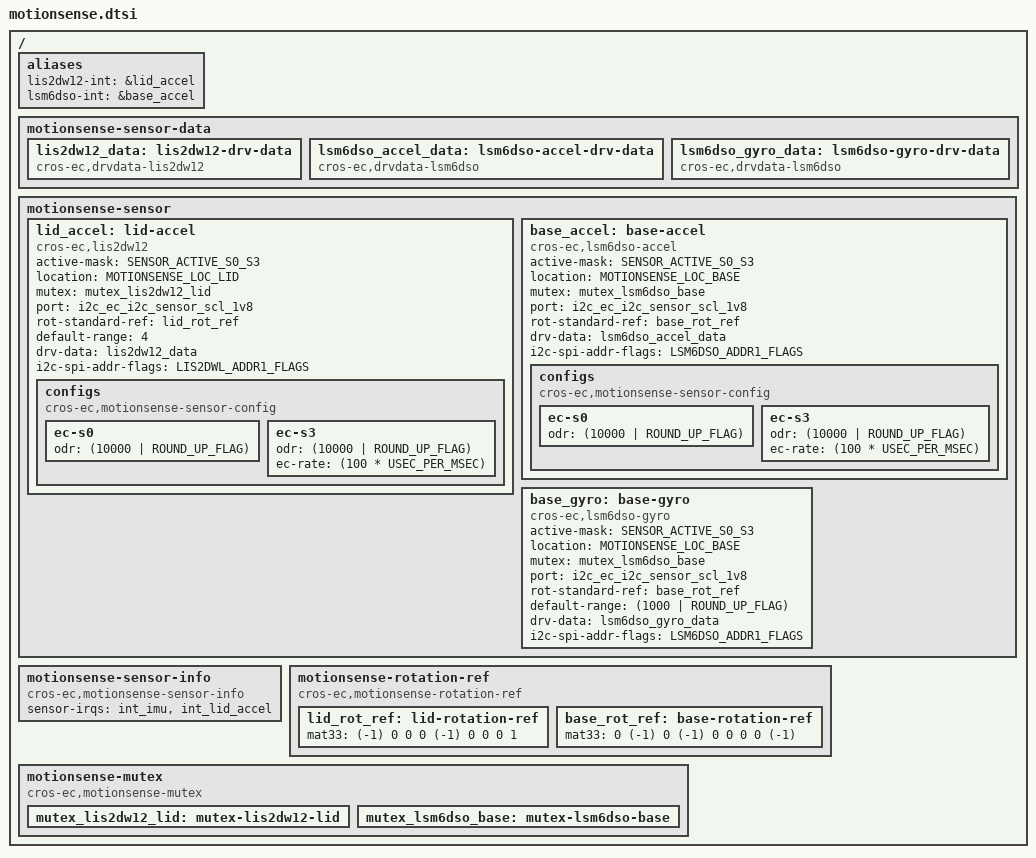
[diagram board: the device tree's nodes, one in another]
/* Copyright 2026 The ChromiumOS Authors
 * Use of this source code is governed by a BSD-style license that can be
 * found in the LICENSE file.
 *
 */

#include <dt-bindings/motionsense/utils.h>

/ {
	aliases {
		/*
		 * motion sense's <>_INT_EVENT is handled
		 * by alias. Using the alias, each driver creates
		 * its own <>_INT_EVENT.
		 */
		lis2dw12-int = &lid_accel;
		lsm6dso-int = &base_accel;
	};

	/*
	 * Driver specific data. A driver-specific data can be shared with
	 * different motion sensors while they are using the same driver.
	 *
	 * If a node's compatible starts with "cros-ec,accelgyro-", it is for
	 * a common structure defined in accelgyro.h.
	 * e.g) compatible = "cros-ec,accelgyro-als-drv-data" is for
	 * "struct als_drv_data_t" in accelgyro.h
	 */
	motionsense-sensor-data {
		lis2dw12_data: lis2dw12-drv-data {
			compatible = "cros-ec,drvdata-lis2dw12";
			status = "okay";
		};

		lsm6dso_accel_data: lsm6dso-accel-drv-data {
			compatible = "cros-ec,drvdata-lsm6dso";
			status = "okay";
		};

		lsm6dso_gyro_data: lsm6dso-gyro-drv-data {
			compatible = "cros-ec,drvdata-lsm6dso";
			status = "okay";
		};
	};

	motionsense-sensor {
		lid_accel: lid-accel {
			compatible = "cros-ec,lis2dw12";
			status = "okay";

			active-mask = "SENSOR_ACTIVE_S0_S3";
			location = "MOTIONSENSE_LOC_LID";
			mutex = <&mutex_lis2dw12_lid>;
			port = <&i2c_ec_i2c_sensor_scl_1v8>;
			rot-standard-ref = <&lid_rot_ref>;
			default-range = <4>; /* to meet CDD 7.3.1/C-1-4 reqs. */
			drv-data = <&lis2dw12_data>;
			i2c-spi-addr-flags = "LIS2DWL_ADDR1_FLAGS";
			configs {
				compatible =
					"cros-ec,motionsense-sensor-config";
				ec-s0 {
					odr = <(10000 | ROUND_UP_FLAG)>;
				};
				ec-s3 {
					odr = <(10000 | ROUND_UP_FLAG)>;
					ec-rate = <(100 * USEC_PER_MSEC)>;
				};
			};
		};

		base_accel: base-accel {
			compatible = "cros-ec,lsm6dso-accel";
			status = "okay";

			active-mask = "SENSOR_ACTIVE_S0_S3";
			location = "MOTIONSENSE_LOC_BASE";
			mutex = <&mutex_lsm6dso_base>;
			port = <&i2c_ec_i2c_sensor_scl_1v8>;
			rot-standard-ref = <&base_rot_ref>;
			drv-data = <&lsm6dso_accel_data>;
			i2c-spi-addr-flags = "LSM6DSO_ADDR1_FLAGS";
			configs {
				compatible =
					"cros-ec,motionsense-sensor-config";
				ec-s0 {
					odr = <(10000 | ROUND_UP_FLAG)>;
				};
				ec-s3 {
					odr = <(10000 | ROUND_UP_FLAG)>;
					ec-rate = <(100 * USEC_PER_MSEC)>;
				};
			};
		};

		base_gyro: base-gyro {
			compatible = "cros-ec,lsm6dso-gyro";
			status = "okay";

			active-mask = "SENSOR_ACTIVE_S0_S3";
			location = "MOTIONSENSE_LOC_BASE";
			mutex = <&mutex_lsm6dso_base>;
			port = <&i2c_ec_i2c_sensor_scl_1v8>;
			rot-standard-ref = <&base_rot_ref>;
			default-range = <(1000 | ROUND_UP_FLAG)>; /* dps */
			drv-data = <&lsm6dso_gyro_data>;
			i2c-spi-addr-flags = "LSM6DSO_ADDR1_FLAGS";
		};
	};

	motionsense-sensor-info {
		compatible = "cros-ec,motionsense-sensor-info";

		/*
		 * list of GPIO interrupts that have to
		 * be enabled at initial stage
		 */
		sensor-irqs = <&int_imu &int_lid_accel>;
	};

	/* Rotation matrix used by drivers. */
	motionsense-rotation-ref {
		compatible = "cros-ec,motionsense-rotation-ref";
		lid_rot_ref: lid-rotation-ref {
			mat33 = <(-1) 0 0
				 0 (-1) 0
				 0 0 1>;
		};
		base_rot_ref: base-rotation-ref {
			mat33 = <0 (-1) 0
				 (-1) 0 0
				 0 0 (-1)>;
		};
	};

	/*
	 * Declare mutexes used by sensor drivers.
	 * A mutex node is used to create an instance of mutex_t.
	 * A mutex node is referenced by a sensor node if the
	 * corresponding sensor driver needs to use the
	 * instance of the mutex.
	 */

	motionsense-mutex {
		compatible = "cros-ec,motionsense-mutex";
		mutex_lis2dw12_lid: mutex-lis2dw12-lid {
		};
		mutex_lsm6dso_base: mutex-lsm6dso-base {
		};
	};

};
